# nrf54h20_enga_radiocore register map
Vendor: Nordic Semiconductor; Series: nRF54h; File version: 1
CPU: CM33 r0p4, little endian, MPU, FPU, 3 interrupt priority bits, 480 interrupts, 4 SAU regions
Registers are 32-bit, read-write, reset 0x0 unless marked. A register's access mark holds for its fields unless they carry their own. Offsets are from the block's base; [hi:lo] are bit positions; lines under a group give offsets from that group; {n}, {i} and the like mark numbered series; 'fields as' and 'values as' point back to an identical list.

## DPPIC020_NS — Distributed programmable peripheral interconnect controller 0
Base 0x43022000
Same registers: DPPIC030_NS 0x43032000, GLOBAL_DPPIC120_NS 0x4F8E1000, GLOBAL_DPPIC130_NS 0x4F922000, GLOBAL_DPPIC131_NS 0x4F981000, GLOBAL_DPPIC132_NS 0x4F991000, GLOBAL_DPPIC133_NS 0x4F9A1000, GLOBAL_DPPIC134_NS 0x4F9B1000, GLOBAL_DPPIC135_NS 0x4F9C1000, GLOBAL_DPPIC136_NS 0x4F9D1000, DPPIC020_S 0x53022000, DPPIC030_S 0x53032000, GLOBAL_DPPIC120_S 0x5F8E1000, GLOBAL_DPPIC130_S 0x5F922000, GLOBAL_DPPIC131_S 0x5F981000, GLOBAL_DPPIC132_S 0x5F991000, GLOBAL_DPPIC133_S 0x5F9A1000, GLOBAL_DPPIC134_S 0x5F9B1000, GLOBAL_DPPIC135_S 0x5F9C1000, GLOBAL_DPPIC136_S 0x5F9D1000
{0x0+8i} TASKS_CHG[{i}] (i=0..1) group — Channel group tasks
  0x00 EN wo — Description cluster: Enable channel group n
    [0] EN — Enable channel group n
      1=Trigger task
  0x04 DIS wo — Description cluster: Disable channel group n
    [0] DIS — Disable channel group n
      1=Trigger task
{0x80+8i} SUBSCRIBE_CHG[{i}] (i=0..1) group — Subscribe configuration for tasks
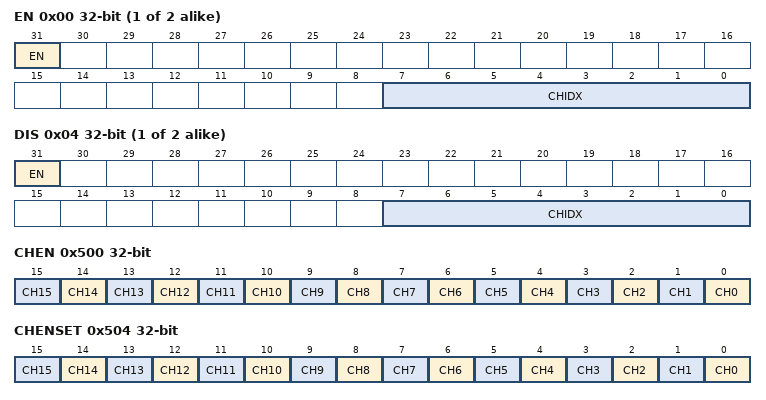
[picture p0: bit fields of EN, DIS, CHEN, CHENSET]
  0x00 EN — Description cluster: Subscribe configuration for task CHG[n].EN
    [31] EN
      0=Disabled (Disable subscription); 1=Enabled (Enable subscription)
    [7:0] CHIDX — DPPI channel that task CHG[n].EN will subscribe to
  0x04 DIS — Description cluster: Subscribe configuration for task CHG[n].DIS
    [31] EN
      values as SUBSCRIBE_CHG[0].EN.EN
    [7:0] CHIDX — DPPI channel that task CHG[n].DIS will subscribe to
0x500 CHEN — Channel enable register
  [all] fields
    0=Disabled (Disable channel); 1=Enabled (Enable channel)
  [n] CH{n} (n=0..15) — Enable or disable channel {n}
0x504 CHENSET write-1-sets — Channel enable set register
  [all] fields
    on read: 0=Disabled (Read: Channel disabled); 1=Enabled (Read: Channel enabled) | on write: 1=Set (Write: Enable channel)
  [n] CH{n} (n=0..15) — Channel {n} enable set register. Writing 0 has no effect.
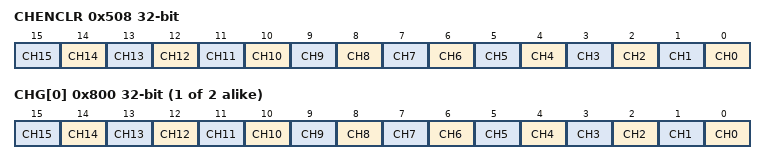
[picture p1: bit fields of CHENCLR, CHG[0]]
0x508 CHENCLR write-1-clears — Channel enable clear register
  [all] fields
    on read: 0=Disabled (Read: Channel disabled); 1=Enabled (Read: Channel enabled) | on write: 1=Clear (Write: Disable channel)
  [n] CH{n} (n=0..15) — Channel {n} enable clear register. Writing 0 has no effect.
{0x800+4i} CHG[{i}] (i=0..1) — Description collection: Channel group n Note: Writes to this register are ignored if either SUBSCRIBE_CHG[n].EN or SUBSCRIBE_CHG[n].DIS is enabled
  [all] fields
    0=Excluded; 1=Included
  [n] CH{n} (n=0..15) — Include or exclude channel {n}

## PPIB020_S — PPIB APB registers 0
Base 0x53023000
Same registers: PPIB030_S 0x53031000
{0x0+4i} TASKS_SEND[{i}] (i=0..31) wo — Description collection: This task is unused, but the PPIB provides the SUBSCRIBE task to connect SEND [n] task.
  [0] TASKS_SEND — This task is unused, but the PPIB provides the SUBSCRIBE task to connect SEND [n] task.
    1=Trigger task
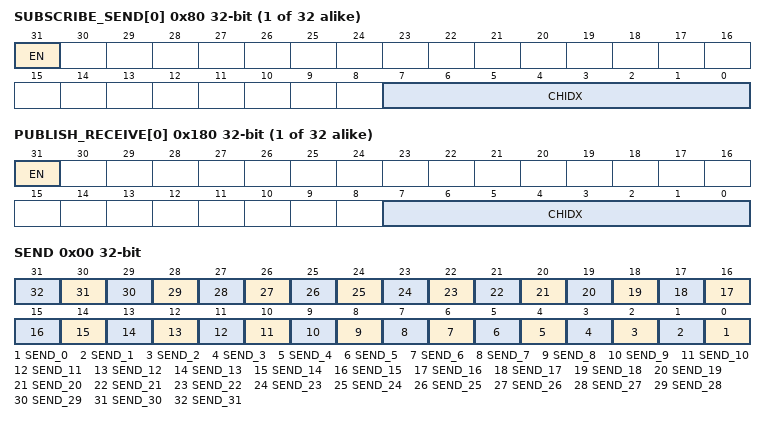
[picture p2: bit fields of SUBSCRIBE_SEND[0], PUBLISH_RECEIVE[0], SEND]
{0x80+4i} SUBSCRIBE_SEND[{i}] (i=0..31) — Description collection: Subscribe configuration for task SEND[n]
  [31] EN
    0=Disabled (Disable subscription); 1=Enabled (Enable subscription)
  [7:0] CHIDX — DPPI channel that task SEND[n] will subscribe to
{0x100+4i} EVENTS_RECEIVE[{i}] (i=0..31) — Description collection: This event is unused, but the PPIB provides the PUBLISH event to connect RECEIVE [n] event.
  [0] EVENTS_RECEIVE — This event is unused, but the PPIB provides the PUBLISH event to connect RECEIVE [n] event.
    0=NotGenerated (Event not generated); 1=Generated (Event generated)
{0x180+4i} PUBLISH_RECEIVE[{i}] (i=0..31) — Description collection: Publish configuration for event RECEIVE[n]
  [31] EN
    0=Disabled (Disable publishing); 1=Enabled (Enable publishing)
  [7:0] CHIDX — DPPI channel that event RECEIVE[n] will publish to
0x400 OVERFLOW group — Unspecified
  0x00 SEND — The task overflow for SEND tasks using SUBSCRIBE_SEND. Write 0 to clear.
    [all] fields
      1=Overflow (Task overflow is happened.); 0=NoOverflow (Task overflow is not happened.)
    [n] SEND_{n} (n=0..31) — The status for tasks overflow at SUBSCRIBE_SEND[{n}].
